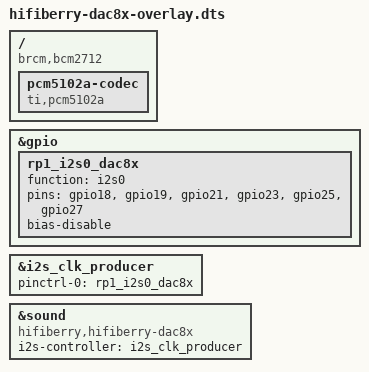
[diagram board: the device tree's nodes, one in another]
// Definitions for HiFiBerry DAC8x
/dts-v1/;
/plugin/;

/ {
	compatible = "brcm,bcm2712";

	fragment@0 {
		target = <&gpio>;
		__overlay__ {
			rp1_i2s0_dac8x: rp1_i2s0_dac8x {
				function = "i2s0";
				pins = "gpio18", "gpio19", "gpio21",
				       "gpio23", "gpio25", "gpio27";
				bias-disable;
				status = "okay";
			};
		};
	};

	fragment@1 {
		target = <&i2s_clk_producer>;
		__overlay__ {
			pinctrl-names = "default";
			pinctrl-0 = <&rp1_i2s0_dac8x>;
			status = "okay";
		};
	};

	fragment@2 {
		target-path = "/";
		__overlay__ {
			pcm5102a-codec {
				#sound-dai-cells = <0>;
				compatible = "ti,pcm5102a";
				status = "okay";
			};
		};
	};

	fragment@3 {
		target = <&sound>;
		__overlay__ {
			compatible = "hifiberry,hifiberry-dac8x";
			i2s-controller = <&i2s_clk_producer>;
			status = "okay";
		};
	};

};
